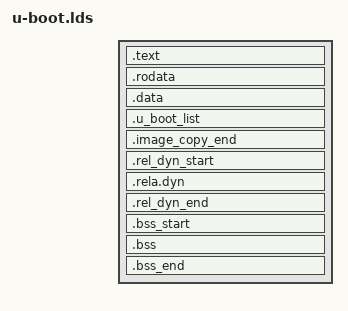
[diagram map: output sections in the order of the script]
/*
 * (C) Copyright 2013
 * David Feng <fenghua@phytium.com.cn>
 *
 * (C) Copyright 2002
 * Gary Jennejohn, DENX Software Engineering, <garyj@denx.de>
 *
 * This file is based on the linker script file arch/arm/cpu/armv8/u-boot.lds
 * u-boot version v2016.01 and modified for alignment required by s32 platforms
 *
 * Copyright 2018 NXP
 *
 * SPDX-License-Identifier:	GPL-2.0+
 */

OUTPUT_FORMAT("elf64-littleaarch64", "elf64-littleaarch64", "elf64-littleaarch64")
OUTPUT_ARCH(aarch64)
ENTRY(_start)
SECTIONS
{
	. = 0x00000000;

	. = ALIGN(8);
	.text :
	{
		*(.__image_copy_start)
		CPUDIR/start.o (.text*)
		*(.text*)
	}

	. = ALIGN(8);
	.rodata : { *(SORT_BY_ALIGNMENT(SORT_BY_NAME(.rodata*))) }

	. = ALIGN(32);
	.data : {
		*(.data*)
	}

	. = ALIGN(8);

	. = .;

	. = ALIGN(8);
	.u_boot_list : {
		KEEP(*(SORT(.u_boot_list*)));
	}

	. = ALIGN(8);

	.image_copy_end :
	{
		*(.__image_copy_end)
	}

	. = ALIGN(8);

	.rel_dyn_start :
	{
		*(.__rel_dyn_start)
	}

	.rela.dyn : {
		*(.rela*)
	}

	.rel_dyn_end :
	{
		*(.__rel_dyn_end)
	}

	_end = .;

	. = ALIGN(32);

	.bss_start : {
		KEEP(*(.__bss_start));
	}

	.bss : {
		*(.bss*)
		 . = ALIGN(32);
	}

	.bss_end : {
		KEEP(*(.__bss_end));
	}

	/DISCARD/ : { *(.dynsym) }
	/DISCARD/ : { *(.dynstr*) }
	/DISCARD/ : { *(.dynamic*) }
	/DISCARD/ : { *(.plt*) }
	/DISCARD/ : { *(.interp*) }
	/DISCARD/ : { *(.gnu*) }
}
